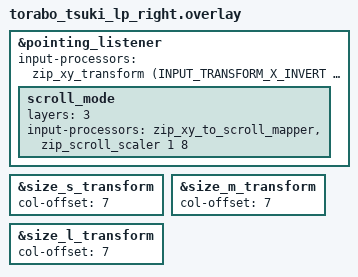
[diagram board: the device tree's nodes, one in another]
#include "torabo_tsuki_lp.dtsi"
#include <input/processors.dtsi>
#include <dt-bindings/zmk/input_transform.h>

&pointing_listener {
    // Default: normal cursor movement (X/Y inverted for sensor orientation)
    input-processors = <&zip_xy_transform (INPUT_TRANSFORM_X_INVERT | INPUT_TRANSFORM_Y_INVERT)>;

    // Layer 3 override: trackball acts as scroll wheel
    // zip_xy_to_scroll_mapper : REL_Y → REL_WHEEL, REL_X → REL_HWHEEL
    // zip_scroll_scaler 1 8   : reduce scroll speed (÷8)
    scroll_mode {
        layers = <3>;
        input-processors =
            <&zip_xy_to_scroll_mapper
             &zip_scroll_scaler 1 8>;
    };
};

&size_s_transform {
    col-offset = <7>;
};

&size_m_transform {
    col-offset = <7>;
};

&size_l_transform {
    col-offset = <7>;
};
